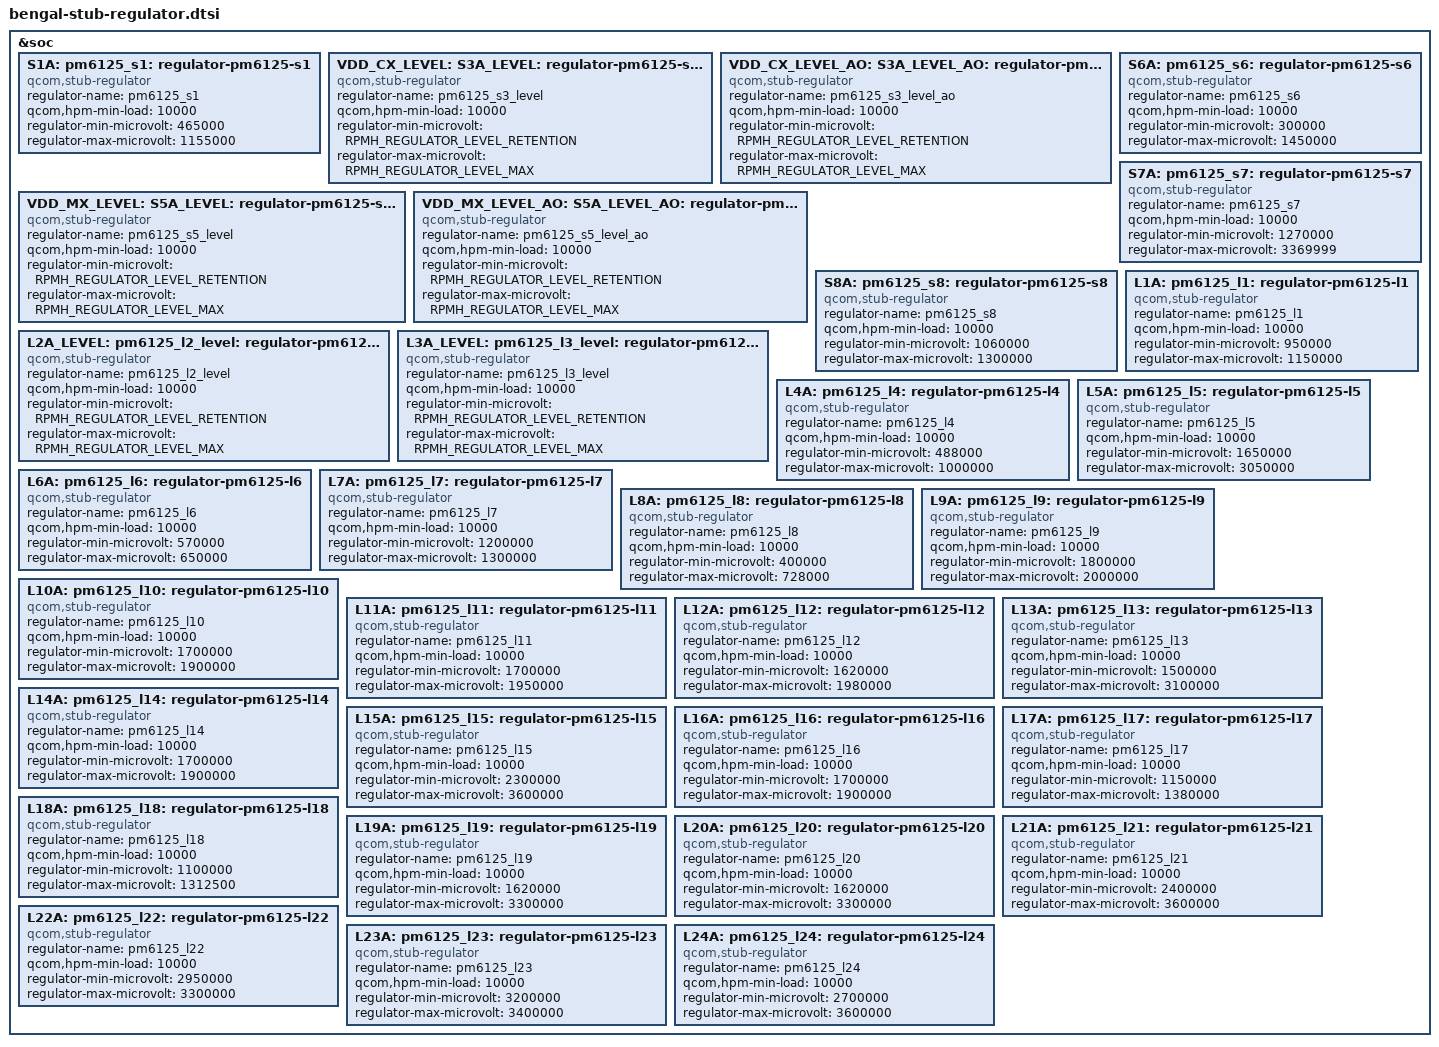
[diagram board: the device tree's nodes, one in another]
#include <dt-bindings/regulator/qcom,rpmh-regulator-levels.h>

&soc {
	S1A: pm6125_s1: regulator-pm6125-s1 {
		compatible = "qcom,stub-regulator";
		regulator-name = "pm6125_s1";
		qcom,hpm-min-load = <10000>;
		regulator-min-microvolt = <465000>;
		regulator-max-microvolt = <1155000>;
	};

	VDD_CX_LEVEL:
	S3A_LEVEL: pm6125_s3_level: regulator-pm6125-s3-level {
		compatible = "qcom,stub-regulator";
		regulator-name = "pm6125_s3_level";
		qcom,hpm-min-load = <10000>;
		regulator-min-microvolt = <RPMH_REGULATOR_LEVEL_RETENTION>;
		regulator-max-microvolt = <RPMH_REGULATOR_LEVEL_MAX>;
	};

	VDD_CX_LEVEL_AO:
	S3A_LEVEL_AO: pm6125_s3_level_ao: regulator-pm6125-s3-level-ao {
		compatible = "qcom,stub-regulator";
		regulator-name = "pm6125_s3_level_ao";
		qcom,hpm-min-load = <10000>;
		regulator-min-microvolt = <RPMH_REGULATOR_LEVEL_RETENTION>;
		regulator-max-microvolt = <RPMH_REGULATOR_LEVEL_MAX>;
	};

	VDD_MX_LEVEL:
	S5A_LEVEL: pm6125_s5_level: regulator-pm6125-s5-level {
		compatible = "qcom,stub-regulator";
		regulator-name = "pm6125_s5_level";
		qcom,hpm-min-load = <10000>;
		regulator-min-microvolt = <RPMH_REGULATOR_LEVEL_RETENTION>;
		regulator-max-microvolt = <RPMH_REGULATOR_LEVEL_MAX>;
	};

	VDD_MX_LEVEL_AO:
	S5A_LEVEL_AO: pm6125_s5_level_ao: regulator-pm6125-s5-level-ao {
		compatible = "qcom,stub-regulator";
		regulator-name = "pm6125_s5_level_ao";
		qcom,hpm-min-load = <10000>;
		regulator-min-microvolt = <RPMH_REGULATOR_LEVEL_RETENTION>;
		regulator-max-microvolt = <RPMH_REGULATOR_LEVEL_MAX>;
	};

	S6A: pm6125_s6: regulator-pm6125-s6 {
		compatible = "qcom,stub-regulator";
		regulator-name = "pm6125_s6";
		qcom,hpm-min-load = <10000>;
		regulator-min-microvolt = <300000>;
		regulator-max-microvolt = <1450000>;
	};

	S7A: pm6125_s7: regulator-pm6125-s7 {
		compatible = "qcom,stub-regulator";
		regulator-name = "pm6125_s7";
		qcom,hpm-min-load = <10000>;
		regulator-min-microvolt = <1270000>;
		regulator-max-microvolt = <3369999>;
	};

	S8A: pm6125_s8: regulator-pm6125-s8 {
		compatible = "qcom,stub-regulator";
		regulator-name = "pm6125_s8";
		qcom,hpm-min-load = <10000>;
		regulator-min-microvolt = <1060000>;
		regulator-max-microvolt = <1300000>;
	};

	L1A: pm6125_l1: regulator-pm6125-l1 {
		compatible = "qcom,stub-regulator";
		regulator-name = "pm6125_l1";
		qcom,hpm-min-load = <10000>;
		regulator-min-microvolt = <950000>;
		regulator-max-microvolt = <1150000>;
	};

	L2A_LEVEL: pm6125_l2_level: regulator-pm6125-l2-level {
		compatible = "qcom,stub-regulator";
		regulator-name = "pm6125_l2_level";
		qcom,hpm-min-load = <10000>;
		regulator-min-microvolt = <RPMH_REGULATOR_LEVEL_RETENTION>;
		regulator-max-microvolt = <RPMH_REGULATOR_LEVEL_MAX>;
	};

	L3A_LEVEL: pm6125_l3_level: regulator-pm6125-l3-level {
		compatible = "qcom,stub-regulator";
		regulator-name = "pm6125_l3_level";
		qcom,hpm-min-load = <10000>;
		regulator-min-microvolt = <RPMH_REGULATOR_LEVEL_RETENTION>;
		regulator-max-microvolt = <RPMH_REGULATOR_LEVEL_MAX>;
	};

	L4A: pm6125_l4: regulator-pm6125-l4 {
		compatible = "qcom,stub-regulator";
		regulator-name = "pm6125_l4";
		qcom,hpm-min-load = <10000>;
		regulator-min-microvolt = <488000>;
		regulator-max-microvolt = <1000000>;
	};

	L5A: pm6125_l5: regulator-pm6125-l5 {
		compatible = "qcom,stub-regulator";
		regulator-name = "pm6125_l5";
		qcom,hpm-min-load = <10000>;
		regulator-min-microvolt = <1650000>;
		regulator-max-microvolt = <3050000>;
	};

	L6A: pm6125_l6: regulator-pm6125-l6 {
		compatible = "qcom,stub-regulator";
		regulator-name = "pm6125_l6";
		qcom,hpm-min-load = <10000>;
		regulator-min-microvolt = <570000>;
		regulator-max-microvolt = <650000>;
	};

	L7A: pm6125_l7: regulator-pm6125-l7 {
		compatible = "qcom,stub-regulator";
		regulator-name = "pm6125_l7";
		qcom,hpm-min-load = <10000>;
		regulator-min-microvolt = <1200000>;
		regulator-max-microvolt = <1300000>;
	};

	L8A: pm6125_l8: regulator-pm6125-l8 {
		compatible = "qcom,stub-regulator";
		regulator-name = "pm6125_l8";
		qcom,hpm-min-load = <10000>;
		regulator-min-microvolt = <400000>;
		regulator-max-microvolt = <728000>;
	};

	L9A: pm6125_l9: regulator-pm6125-l9 {
		compatible = "qcom,stub-regulator";
		regulator-name = "pm6125_l9";
		qcom,hpm-min-load = <10000>;
		regulator-min-microvolt = <1800000>;
		regulator-max-microvolt = <2000000>;
	};

	L10A: pm6125_l10: regulator-pm6125-l10 {
		compatible = "qcom,stub-regulator";
		regulator-name = "pm6125_l10";
		qcom,hpm-min-load = <10000>;
		regulator-min-microvolt = <1700000>;
		regulator-max-microvolt = <1900000>;
	};

	L11A: pm6125_l11: regulator-pm6125-l11 {
		compatible = "qcom,stub-regulator";
		regulator-name = "pm6125_l11";
		qcom,hpm-min-load = <10000>;
		regulator-min-microvolt = <1700000>;
		regulator-max-microvolt = <1950000>;
	};

	L12A: pm6125_l12: regulator-pm6125-l12 {
		compatible = "qcom,stub-regulator";
		regulator-name = "pm6125_l12";
		qcom,hpm-min-load = <10000>;
		regulator-min-microvolt = <1620000>;
		regulator-max-microvolt = <1980000>;
	};

	L13A: pm6125_l13: regulator-pm6125-l13 {
		compatible = "qcom,stub-regulator";
		regulator-name = "pm6125_l13";
		qcom,hpm-min-load = <10000>;
		regulator-min-microvolt = <1500000>;
		regulator-max-microvolt = <3100000>;
	};

	L14A: pm6125_l14: regulator-pm6125-l14 {
		compatible = "qcom,stub-regulator";
		regulator-name = "pm6125_l14";
		qcom,hpm-min-load = <10000>;
		regulator-min-microvolt = <1700000>;
		regulator-max-microvolt = <1900000>;
	};

	L15A: pm6125_l15: regulator-pm6125-l15 {
		compatible = "qcom,stub-regulator";
		regulator-name = "pm6125_l15";
		qcom,hpm-min-load = <10000>;
		regulator-min-microvolt = <2300000>;
		regulator-max-microvolt = <3600000>;
	};

	L16A: pm6125_l16: regulator-pm6125-l16 {
		compatible = "qcom,stub-regulator";
		regulator-name = "pm6125_l16";
		qcom,hpm-min-load = <10000>;
		regulator-min-microvolt = <1700000>;
		regulator-max-microvolt = <1900000>;
	};

	L17A: pm6125_l17: regulator-pm6125-l17 {
		compatible = "qcom,stub-regulator";
		regulator-name = "pm6125_l17";
		qcom,hpm-min-load = <10000>;
		regulator-min-microvolt = <1150000>;
		regulator-max-microvolt = <1380000>;
	};

	L18A: pm6125_l18: regulator-pm6125-l18 {
		compatible = "qcom,stub-regulator";
		regulator-name = "pm6125_l18";
		qcom,hpm-min-load = <10000>;
		regulator-min-microvolt = <1100000>;
		regulator-max-microvolt = <1312500>;
	};

	L19A: pm6125_l19: regulator-pm6125-l19 {
		compatible = "qcom,stub-regulator";
		regulator-name = "pm6125_l19";
		qcom,hpm-min-load = <10000>;
		regulator-min-microvolt = <1620000>;
		regulator-max-microvolt = <3300000>;
	};

	L20A: pm6125_l20: regulator-pm6125-l20 {
		compatible = "qcom,stub-regulator";
		regulator-name = "pm6125_l20";
		qcom,hpm-min-load = <10000>;
		regulator-min-microvolt = <1620000>;
		regulator-max-microvolt = <3300000>;
	};

	L21A: pm6125_l21: regulator-pm6125-l21 {
		compatible = "qcom,stub-regulator";
		regulator-name = "pm6125_l21";
		qcom,hpm-min-load = <10000>;
		regulator-min-microvolt = <2400000>;
		regulator-max-microvolt = <3600000>;
	};

	L22A: pm6125_l22: regulator-pm6125-l22 {
		compatible = "qcom,stub-regulator";
		regulator-name = "pm6125_l22";
		qcom,hpm-min-load = <10000>;
		regulator-min-microvolt = <2950000>;
		regulator-max-microvolt = <3300000>;
	};

	L23A: pm6125_l23: regulator-pm6125-l23 {
		compatible = "qcom,stub-regulator";
		regulator-name = "pm6125_l23";
		qcom,hpm-min-load = <10000>;
		regulator-min-microvolt = <3200000>;
		regulator-max-microvolt = <3400000>;
	};

	L24A: pm6125_l24: regulator-pm6125-l24 {
		compatible = "qcom,stub-regulator";
		regulator-name = "pm6125_l24";
		qcom,hpm-min-load = <10000>;
		regulator-min-microvolt = <2700000>;
		regulator-max-microvolt = <3600000>;
	};
};
